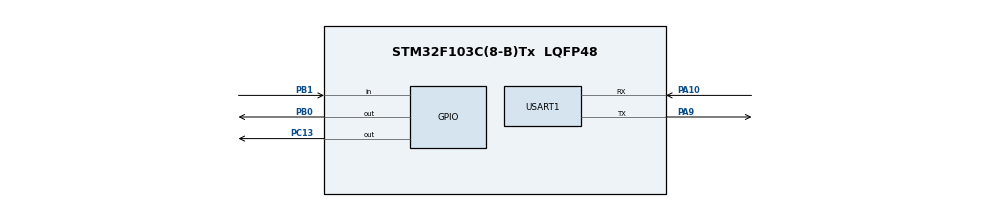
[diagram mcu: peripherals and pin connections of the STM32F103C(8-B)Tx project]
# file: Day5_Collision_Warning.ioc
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Mcu.Family=STM32F1
Mcu.Name=STM32F103C(8-B)Tx
Mcu.Package=LQFP48
NVIC.PriorityGroup=NVIC_PRIORITYGROUP_4
PA10.Mode=Asynchronous
PA10.Signal=USART1_RX
PA9.Mode=Asynchronous
PA9.Signal=USART1_TX
PB0.Signal=GPIO_Output
PB1.Signal=GPIO_Input
PC13-TAMPER-RTC.Signal=GPIO_Output
ProjectManager.HeapSize=0x200
ProjectManager.StackSize=0x400
ProjectManager.TargetToolchain=STM32CubeIDE
RCC.APB1Freq_Value=8000000
RCC.APB2Freq_Value=8000000
TIM2.Prescaler=71
USART1.VirtualMode=VM_ASYNC
VP_SYS_VS_ND.Mode=No_Debug
VP_TIM2_VS_ClockSourceINT.Mode=Internal
board=custom

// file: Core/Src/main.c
/* USER CODE BEGIN Header */
/**
  ******************************************************************************
  * @file           : main.c
  * @brief          : Main program body
  ******************************************************************************
  * @attention
  *
  * Copyright (c) 2026 STMicroelectronics.
  * All rights reserved.
  *
  * This software is licensed under terms that can be found in the LICENSE file
  * in the root directory of this software component.
  * If no LICENSE file comes with this software, it is provided AS-IS.
  *
  ******************************************************************************
  */
/* USER CODE END Header */
#include "main.h"
#include <stdio.h>
#include <string.h>

TIM_HandleTypeDef htim2;

UART_HandleTypeDef huart1;

/* USER CODE BEGIN PV */
uint32_t time = 0;

float distance = 0;

char msg[100];

/* USER CODE END PV */

void SystemClock_Config(void);
static void MX_GPIO_Init(void);
static void MX_TIM2_Init(void);
static void MX_USART1_UART_Init(void);

void delay_us(uint16_t us)
{
    __HAL_TIM_SET_COUNTER(&htim2, 0);

    while(__HAL_TIM_GET_COUNTER(&htim2) < us);
}
int main(void)
{

  /* MCU Configuration--------------------------------------------------------*/

  /* Reset of all peripherals, Initializes the Flash interface and the Systick. */
  HAL_Init();

  /* Configure the system clock */
  SystemClock_Config();

  /* Initialize all configured peripherals */
  MX_GPIO_Init();
  MX_TIM2_Init();
  MX_USART1_UART_Init();
  /* USER CODE BEGIN 2 */
  HAL_TIM_Base_Start(&htim2);

  /* USER CODE END 2 */

  /* Infinite loop */
  /* USER CODE BEGIN WHILE */
  while (1)
  {
      HAL_GPIO_WritePin(GPIOB, GPIO_PIN_0, GPIO_PIN_RESET);
      delay_us(2);

      HAL_GPIO_WritePin(GPIOB, GPIO_PIN_0, GPIO_PIN_SET);
      delay_us(10);

      HAL_GPIO_WritePin(GPIOB, GPIO_PIN_0, GPIO_PIN_RESET);

      while(HAL_GPIO_ReadPin(GPIOB, GPIO_PIN_1) == GPIO_PIN_RESET);

      __HAL_TIM_SET_COUNTER(&htim2, 0);

      while(HAL_GPIO_ReadPin(GPIOB, GPIO_PIN_1) == GPIO_PIN_SET);

      time = __HAL_TIM_GET_COUNTER(&htim2);

      distance = time * 0.034 / 2;

      uint32_t dist_int;

      dist_int = (uint32_t)distance;

      if(dist_int > 50)
      {
          HAL_GPIO_WritePin(GPIOC,
                            GPIO_PIN_13,
                            GPIO_PIN_RESET);

          sprintf(msg,
                  "Distance: %lu cm SAFE\r\n",
                  dist_int);
      }

      else if(dist_int > 20)
      {
          HAL_GPIO_TogglePin(GPIOC,
                             GPIO_PIN_13);

          sprintf(msg,
                  "Distance: %lu cm WARNING\r\n",
                  dist_int);
      }

      else
      {
          HAL_GPIO_WritePin(GPIOC,
                            GPIO_PIN_13,
                            GPIO_PIN_SET);

          sprintf(msg,
                  "Distance: %lu cm DANGER\r\n",
                  dist_int);
      }

      HAL_UART_Transmit(&huart1,
                        (uint8_t*)msg,
                        strlen(msg),
                        HAL_MAX_DELAY);

      HAL_Delay(300);
  }
  /* USER CODE END 3 */
}

void SystemClock_Config(void)
{
  RCC_OscInitTypeDef RCC_OscInitStruct = {0};
  RCC_ClkInitTypeDef RCC_ClkInitStruct = {0};

  /** Initializes the RCC Oscillators according to the specified parameters
  * in the RCC_OscInitTypeDef structure.
  */
  RCC_OscInitStruct.OscillatorType = RCC_OSCILLATORTYPE_HSI;
  RCC_OscInitStruct.HSIState = RCC_HSI_ON;
  RCC_OscInitStruct.HSICalibrationValue = RCC_HSICALIBRATION_DEFAULT;
  RCC_OscInitStruct.PLL.PLLState = RCC_PLL_NONE;
  if (HAL_RCC_OscConfig(&RCC_OscInitStruct) != HAL_OK)
  {
    Error_Handler();
  }

  /** Initializes the CPU, AHB and APB buses clocks
  */
  RCC_ClkInitStruct.ClockType = RCC_CLOCKTYPE_HCLK|RCC_CLOCKTYPE_SYSCLK
                              |RCC_CLOCKTYPE_PCLK1|RCC_CLOCKTYPE_PCLK2;
  RCC_ClkInitStruct.SYSCLKSource = RCC_SYSCLKSOURCE_HSI;
  RCC_ClkInitStruct.AHBCLKDivider = RCC_SYSCLK_DIV1;
  RCC_ClkInitStruct.APB1CLKDivider = RCC_HCLK_DIV1;
  RCC_ClkInitStruct.APB2CLKDivider = RCC_HCLK_DIV1;

  if (HAL_RCC_ClockConfig(&RCC_ClkInitStruct, FLASH_LATENCY_0) != HAL_OK)
  {
    Error_Handler();
  }
}

static void MX_TIM2_Init(void)
{

  TIM_ClockConfigTypeDef sClockSourceConfig = {0};
  TIM_MasterConfigTypeDef sMasterConfig = {0};

  htim2.Instance = TIM2;
  htim2.Init.Prescaler = 71;
  htim2.Init.CounterMode = TIM_COUNTERMODE_UP;
  htim2.Init.Period = 65535;
  htim2.Init.ClockDivision = TIM_CLOCKDIVISION_DIV1;
  htim2.Init.AutoReloadPreload = TIM_AUTORELOAD_PRELOAD_DISABLE;
  if (HAL_TIM_Base_Init(&htim2) != HAL_OK)
  {
    Error_Handler();
  }
  sClockSourceConfig.ClockSource = TIM_CLOCKSOURCE_INTERNAL;
  if (HAL_TIM_ConfigClockSource(&htim2, &sClockSourceConfig) != HAL_OK)
  {
    Error_Handler();
  }
  sMasterConfig.MasterOutputTrigger = TIM_TRGO_RESET;
  sMasterConfig.MasterSlaveMode = TIM_MASTERSLAVEMODE_DISABLE;
  if (HAL_TIMEx_MasterConfigSynchronization(&htim2, &sMasterConfig) != HAL_OK)
  {
    Error_Handler();
  }

}

static void MX_USART1_UART_Init(void)
{

  huart1.Instance = USART1;
  huart1.Init.BaudRate = 115200;
  huart1.Init.WordLength = UART_WORDLENGTH_8B;
  huart1.Init.StopBits = UART_STOPBITS_1;
  huart1.Init.Parity = UART_PARITY_NONE;
  huart1.Init.Mode = UART_MODE_TX_RX;
  huart1.Init.HwFlowCtl = UART_HWCONTROL_NONE;
  huart1.Init.OverSampling = UART_OVERSAMPLING_16;
  if (HAL_UART_Init(&huart1) != HAL_OK)
  {
    Error_Handler();
  }

}

static void MX_GPIO_Init(void)
{
  GPIO_InitTypeDef GPIO_InitStruct = {0};

  /* GPIO Ports Clock Enable */
  __HAL_RCC_GPIOC_CLK_ENABLE();
  __HAL_RCC_GPIOB_CLK_ENABLE();
  __HAL_RCC_GPIOA_CLK_ENABLE();

  /*Configure GPIO pin Output Level */
  HAL_GPIO_WritePin(GPIOC, GPIO_PIN_13, GPIO_PIN_RESET);

  /*Configure GPIO pin Output Level */
  HAL_GPIO_WritePin(GPIOB, GPIO_PIN_0, GPIO_PIN_RESET);

  /*Configure GPIO pin : PC13 */
  GPIO_InitStruct.Pin = GPIO_PIN_13;
  GPIO_InitStruct.Mode = GPIO_MODE_OUTPUT_PP;
  GPIO_InitStruct.Pull = GPIO_NOPULL;
  GPIO_InitStruct.Speed = GPIO_SPEED_FREQ_LOW;
  HAL_GPIO_Init(GPIOC, &GPIO_InitStruct);

  /*Configure GPIO pin : PB0 */
  GPIO_InitStruct.Pin = GPIO_PIN_0;
  GPIO_InitStruct.Mode = GPIO_MODE_OUTPUT_PP;
  GPIO_InitStruct.Pull = GPIO_NOPULL;
  GPIO_InitStruct.Speed = GPIO_SPEED_FREQ_LOW;
  HAL_GPIO_Init(GPIOB, &GPIO_InitStruct);

  /*Configure GPIO pin : PB1 */
  GPIO_InitStruct.Pin = GPIO_PIN_1;
  GPIO_InitStruct.Mode = GPIO_MODE_INPUT;
  GPIO_InitStruct.Pull = GPIO_NOPULL;
  HAL_GPIO_Init(GPIOB, &GPIO_InitStruct);

}

void Error_Handler(void)
{
  __disable_irq();
  while (1)
  {
  }
}
